# MAX32520 register map
Vendor: Maxim-Integrated; Series: ARMCM4; File version: 1.0
MAX32520 32-bit ARM Cortex-M4 microcontroller, 1024KB of flash, 760KB of system RAM, 128KB of Boot ROM.
CPU: CM4 r2p1, little endian, MPU, FPU, 3 interrupt priority bits
Registers are 32-bit, read-write, reset 0x0 unless marked. A register's access mark holds for its fields unless they carry their own. Offsets are from the block's base; lines under a group give offsets from that group; [hi:lo] are bit positions; {n}, {i} and the like mark numbered series; 'fields as' and 'values as' point back to an identical list; <NAME> marks a mode.

## Memory map
0x40000000 GCR size 0x400 — Global Control Registers.
0x40000400 SIR size 0x400 — System Initialization Registers.
0x40000800 FCR size 0x400 — Function Control Register.
0x40001000 CTB size 0x1000 — The Cryptographic Toolbox is a combination of cryptographic engines and a secure cryptographic accelerator (SCA) used to provide advanced cryptographic security.
0x40003000 WDT0 size 0x400 — Watchdog Timer 0
0x40003400 WDT1 size 0x400 — Watchdog Timer 0 1
0x40004000 SMON size 0x400 — The Security Monitor block used to monitor system threat conditions.
0x40005000 AES size 0x400 — AES Keys.
0x40006800 PWRSEQ size 0x800 — Power Sequencer / Low Power Control Register.
0x40006C00 MCR size 0x400 — Misc Control.
0x40008000 GPIO0 size 0x1000 — Individual I/O for each GPIO
0x40009000 GPIO1 size 0x1000 — Individual I/O for each GPIO 1
0x40010000 TMR0 size 0x1000 — 32-bit reloadable timer that can be used for timing and event counting.
0x40011000 TMR1 size 0x1000 — 32-bit reloadable timer that can be used for timing and event counting. 1
0x40012000 TMR2 size 0x1000 — 32-bit reloadable timer that can be used for timing and event counting. 2
0x40013000 TMR3 size 0x1000 — 32-bit reloadable timer that can be used for timing and event counting. 3
0x4001D000 I2C0 size 0x1000 — Inter-Integrated Circuit.
0x40020000 UART0 size 0x1000 — UART
0x40028000 DMA size 0x1000 — DMA Controller Fully programmable, chaining capable DMA channels.
0x40029000 FLC size 0x1000 — Flash Memory Control.
0x4002A000 ICC0 size 0x1000 — Instruction Cache Controller Registers
0x4002F000 ICC1 size 0x1000 — Instruction Cache Controller Registers 1
0x40046000 SPI0 size 0x1000 — SPI peripheral.
0x40047000 SPI1 size 0x1000 — SPI peripheral. 1
0x4004D000 TRNG size 0x1000 — Random Number Generator.
0x400A0000 SFE size 0x1000 — Serial Flash Emulator.

## Interrupts
1 WDT0
4 TRNG — TRNG interrupt.
5 TMR0 — TMR0 IRQ
6 TMR1 — TMR1 IRQ
7 TMR2 — TMR2 IRQ
8 TMR3 — TMR3 IRQ
13 I2C0 — I2C0 IRQ
14 UART0 — UART0 IRQ
16 SPI0
17 SPI1 — SPI1 IRQ
23 Flash_Controller (FLC) — Flash Controller interrupt.
24 GPIO0 — GPIO0 interrupt.
25 GPIO1 — GPIO1 IRQ
27 Crypto_Engine (CTB) — Crypto Engine interrupt.
28 DMA0 (DMA)
29 DMA1 (DMA)
30 DMA2 (DMA)
31 DMA3 (DMA)
57 WDT1 — WDT1 IRQ

## AES — AES Keys.
Base 0x40005000
0x00 AES_SRAM_KEY
0x80 AES_CODE_KEY
0x100 AES_DATA_KEY

## FCR — Function Control Register.
Base 0x40000800
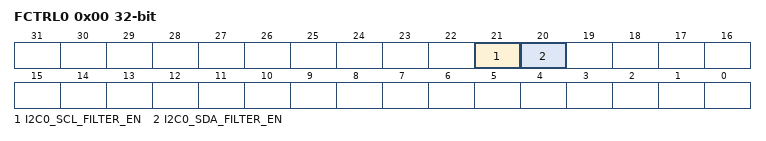
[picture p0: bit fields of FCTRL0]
0x00 FCTRL0 — Register 0.
  [21] I2C0_SCL_FILTER_EN — I2C0 SCL Glitch Filter Enable.
    0=dis (Filter disabled.); 1=en (Filter enabled.)
  [20] I2C0_SDA_FILTER_EN — I2C0 SDA Glitch Filter Enable.
    0=dis (Filter disabled.); 1=en (Filter enabled.)

## MCR — Misc Control.
Base 0x40006C00
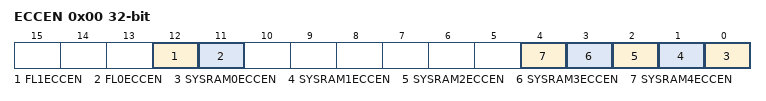
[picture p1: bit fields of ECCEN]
0x00 ECCEN — ECC Enable Register
  [all] fields
    0=dis (disabled.); 1=en (enabled.)
  [12] FL1ECCEN — Flash1 ECC Enable.
  [11] FL0ECCEN — Flash0 ECC Enable.
  [n] SYSRAM{n}ECCEN (n=0..4) — ECC System RAM Enable.

## FLC — Flash Memory Control.
Base 0x40029000; register names take the prefix FLSH_
0x00 FLSH_ADDR — Flash Write Address.
  [31:0] ADDR — Address for next operation.
0x04 FLSH_CLKDIV reset 0x64 — Flash Clock Divide. The clock (PLL0) is divided by this value to generate a 1 MHz clock for Flash controller.
  [7:0] CLKDIV — Flash Clock Divide. The clock is divided by this value to generate a 1MHz clock for flash controller.
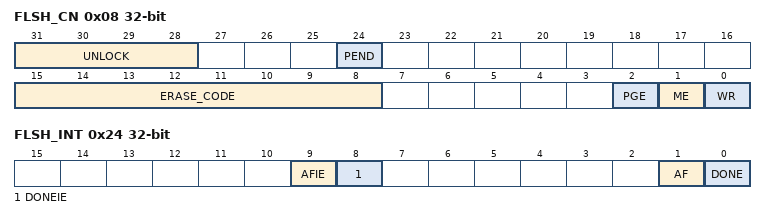
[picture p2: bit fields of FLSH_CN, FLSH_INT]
0x08 FLSH_CN — Flash Control Register.
  [31:28] UNLOCK — Flash Unlock. The correct unlock code must be written to these four bits before any Flash write or erase operation is allowed.
    2=unlocked (Flash Unlocked.); 3=locked (Flash Locked.)
  [24] PEND ro — Flash Pending. When Flash operation is in progress (busy), Flash reads and writes will fail. When PEND is set, write to all Flash registers, with exception of the Flash interrupt register, are ignored.
    0=idle; 1=busy
  [15:8] ERASE_CODE — Erase Code. The ERASE_CODE must be set up property before erase operation can be initiated. These bits are automatically cleared after the operation is complete.
    0=nop (No operation.); 85=erasePage (Enable Page Erase.); 170=eraseAll (Enable Mass Erase. The debug port must be enabled.)
  [2] PGE — Page Erase. This bit is automatically cleared after the operation.
    0=complete (No operation/complete.); 1=Start operation
  [1] ME — Mass Erase. This bit is automatically cleared after the operation.
    0=complete (No operation/complete.); 1=Start operation
  [0] WR — Write. This bit is automatically cleared after the operation.
    0=complete (No operation/complete.); 1=Start operation
0x24 FLSH_INT — Flash Interrupt Register.
  [9] AFIE — Flash Done Interrupt Enable.
    0=disable; 1=enable
  [8] DONEIE — Flash Done Interrupt Enable.
    0=disable; 1=enable
  [1] AF — Flash Access Fail. This bit is set when an attempt is made to write the flash while the flash is busy or the flash is locked. This bit can only be set to 1 by hardware.
    0=noError (No Failure.); 1=error (Failure occurs.)
  [0] DONE — Flash Done Interrupt. This bit is set to 1 upon Flash write or erase completion.
    0=inactive (No interrupt is pending.); 1=pending (An interrupt is pending.)
{0x30+4i} FLSH_DATA[{i}] (i=0..3) — Flash Write Data.
  [31:0] DATA — Data next operation.
0x40 ACNTL wo — Access Control Register. Writing the ACTRL register with the following values in the order shown, allows read and write access to the system and user Information block: pflc-actrl = 0x3a7f5ca3; pflc-actrl = 0xa1e34f20; pflc-actrl = 0x9608b2c1. When unlocked, a write of any word will disable access to system and user information block. Readback of this register is always zero.
  [31:0] ADATA — Access control.
